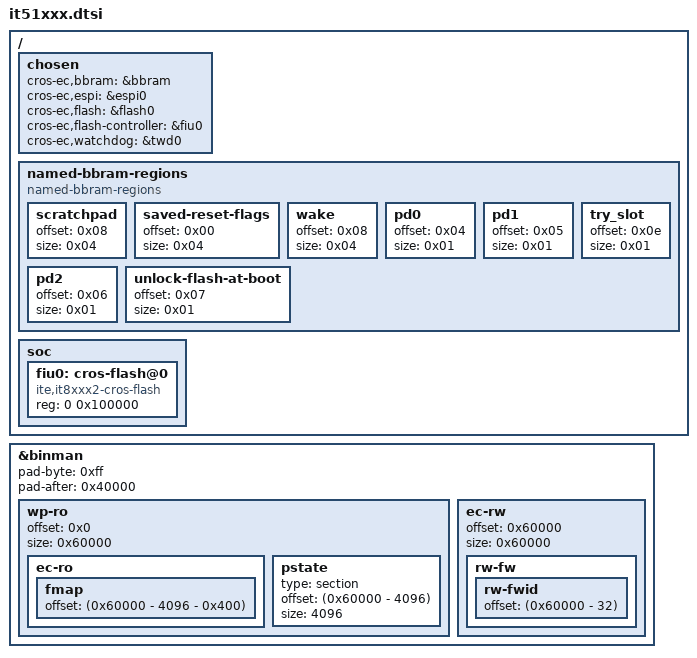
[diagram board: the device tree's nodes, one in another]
/* Copyright 2021 The ChromiumOS Authors
 * Use of this source code is governed by a BSD-style license that can be
 * found in the LICENSE file.
 */

#include <cros/binman.dtsi>

/ {
	chosen {
		cros-ec,bbram = &bbram;
		cros-ec,espi = &espi0;
		cros-ec,flash = &flash0;
		cros-ec,flash-controller = &fiu0;
		cros-ec,watchdog = &twd0;
	};

	named-bbram-regions {
		compatible = "named-bbram-regions";

		scratchpad {
			offset = <0x08>;
			size = <0x04>;
		};
		saved-reset-flags {
			offset = <0x00>;
			size = <0x04>;
		};
		wake {
			offset = <0x08>;
			size = <0x04>;
		};
		pd0 {
			offset = <0x04>;
			size = <0x01>;
		};
		pd1 {
			offset = <0x05>;
			size = <0x01>;
		};
		try_slot {
			offset = <0x0e>;
			size = <0x01>;
		};
		pd2 {
			offset = <0x06>;
			size = <0x01>;
		};
		unlock-flash-at-boot {
			offset = <0x07>;
			size = <0x01>;
		};
	};

	soc {
		fiu0: cros-flash@0 {
			compatible = "ite,it8xxx2-cros-flash";
			reg = <0 0x100000>;
		};


	};

};

&binman {
	wp-ro {
		offset = <0x0>;
		size = <0x60000>;

		ec-ro {
			fmap {
				offset = <(0x60000 - 4096 - 0x400)>;
				/*
				 * don't specify 'size = <0x400>' here so
				 * it is auto-assigned to the fmap size.
				 */
			};
		};
		pstate: pstate {
			type = "section";
			offset = <(0x60000 - 4096)>;
			size = <4096>;
		};
	};
	ec-rw {
		offset = <0x60000>;
		size = <0x60000>;
		rw-fw {
			rw-fwid {
				/* Fix the lcoation of the FWID to the
				 * last 32 bytes of the flash. This
				 * ensures the RW entries in the FMAP
				 * stored in the RO section of flash
				 * are always correct.
				 */
				offset = <(0x60000 - 32)>;
			};
		};
	};
	pad-byte = <0xff>;
	pad-after = <0x40000>;
};
